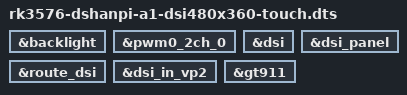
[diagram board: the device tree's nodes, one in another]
/dts-v1/;
/plugin/;
/ {
	fragment@0 {
		target = <&backlight>;
		__overlay__ {
			status = "okay";
		};
	};

	fragment@1 {
		target = <&pwm0_2ch_0>;
		__overlay__ {
			status = "okay";
		};
	};

	fragment@2 {
		target = <&dsi>;
		__overlay__ {
			status = "okay";
		};
	};

	fragment@3 {
		target = <&dsi_panel>;
		__overlay__ {
			status = "okay";
		};
	};

	fragment@4 {
		target = <&route_dsi>;
		__overlay__ {
			status = "okay";
		};
	};

	fragment@5 {
		target = <&dsi_in_vp2>;
		__overlay__ {
			status = "okay";
		};
	};

	fragment@6 {
		target = <&gt911>;
		__overlay__ {
			status = "okay";
		};
	};
};
